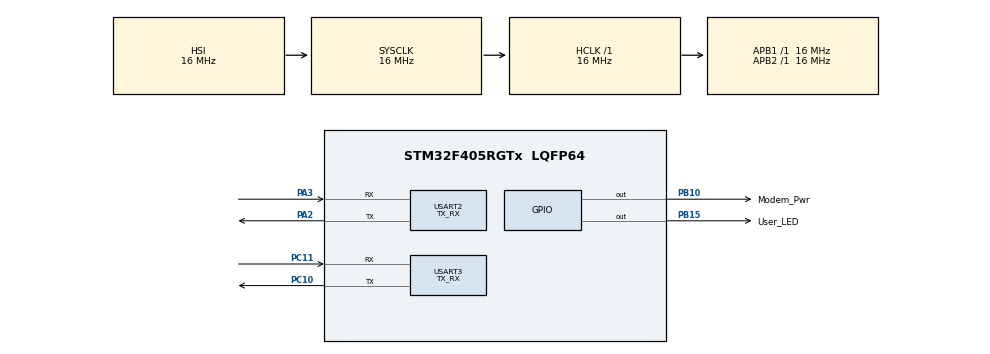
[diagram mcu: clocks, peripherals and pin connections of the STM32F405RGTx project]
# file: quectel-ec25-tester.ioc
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Dma.Request0=USART3_RX
Dma.Request1=USART2_RX
Dma.USART2_RX.1.Direction=DMA_PERIPH_TO_MEMORY
Dma.USART2_RX.1.FIFOMode=DMA_FIFOMODE_DISABLE
Dma.USART2_RX.1.Instance=DMA1_Stream5
Dma.USART2_RX.1.MemDataAlignment=DMA_MDATAALIGN_BYTE
Dma.USART2_RX.1.MemInc=DMA_MINC_ENABLE
Dma.USART2_RX.1.Mode=DMA_CIRCULAR
Dma.USART2_RX.1.PeriphDataAlignment=DMA_PDATAALIGN_BYTE
Dma.USART2_RX.1.PeriphInc=DMA_PINC_DISABLE
Dma.USART2_RX.1.Priority=DMA_PRIORITY_LOW
Dma.USART3_RX.0.Direction=DMA_PERIPH_TO_MEMORY
Dma.USART3_RX.0.FIFOMode=DMA_FIFOMODE_DISABLE
Dma.USART3_RX.0.Instance=DMA1_Stream1
Dma.USART3_RX.0.MemDataAlignment=DMA_MDATAALIGN_BYTE
Dma.USART3_RX.0.MemInc=DMA_MINC_ENABLE
Dma.USART3_RX.0.Mode=DMA_CIRCULAR
Dma.USART3_RX.0.PeriphDataAlignment=DMA_PDATAALIGN_BYTE
Dma.USART3_RX.0.PeriphInc=DMA_PINC_DISABLE
Dma.USART3_RX.0.Priority=DMA_PRIORITY_LOW
FREERTOS.Events01=FreeRTOS_Event_MQTT,Static,FreeRTOS_Event_MQTTControlBlock
FREERTOS.Mutexes01=ModemMutex,Static,ModemMutexControlBlock;MqttMutex,Static,MqttMutexControlBlock
FREERTOS.Tasks01=OS_Thread,24,512,OS_Run,As weak,NULL,Static,OS_ThreadBuffer,OS_ThreadControlBlock;Modem_Thread,8,1024,MDM_Run,As external,NULL,Static,Modem_ThreadBuffer,Modem_ThreadControlBlock;MQTT_Thread,8,1024,MQTT_Run,As external,NULL,Static,MQTT_ThreadBuffer,MQTT_ThreadControlBlock
FREERTOS.configUSE_NEWLIB_REENTRANT=1
Mcu.Family=STM32F4
Mcu.Name=STM32F405RGTx
Mcu.Package=LQFP64
NVIC.DMA1_Stream1_IRQn=true\:5\:0\:false\:false\:true\:true\:false\:true\:true
NVIC.DMA1_Stream5_IRQn=true\:5\:0\:false\:false\:true\:true\:false\:true\:true
NVIC.HASH_RNG_IRQn=true\:5\:0\:false\:false\:true\:true\:true\:true\:true
NVIC.PriorityGroup=NVIC_PRIORITYGROUP_4
NVIC.TIM1_UP_TIM10_IRQn=true\:15\:0\:false\:false\:true\:false\:false\:true\:true
NVIC.TimeBase=TIM1_UP_TIM10_IRQn
NVIC.TimeBaseIP=TIM1
NVIC.USART2_IRQn=true\:5\:0\:false\:false\:true\:true\:true\:true\:true
NVIC.USART3_IRQn=true\:5\:0\:false\:false\:true\:true\:true\:true\:true
PA13.Mode=Serial_Wire
PA13.Signal=SYS_JTMS-SWDIO
PA14.Mode=Serial_Wire
PA14.Signal=SYS_JTCK-SWCLK
PA2.Mode=Asynchronous
PA2.Signal=USART2_TX
PA3.Mode=Asynchronous
PA3.Signal=USART2_RX
PB10.GPIO_Label=Modem_Pwr
PB10.Signal=GPIO_Output
PB15.GPIO_Label=User_LED
PB15.Signal=GPIO_Output
PC10.Mode=Asynchronous
PC10.Signal=USART3_TX
PC11.Mode=Asynchronous
PC11.Signal=USART3_RX
ProjectManager.HeapSize=0x200
ProjectManager.StackSize=0x400
ProjectManager.TargetToolchain=STM32CubeIDE
RCC.AHBFreq_Value=16000000
RCC.APB1Freq_Value=16000000
RCC.APB2Freq_Value=16000000
RCC.CortexFreq_Value=16000000
RCC.HSE_VALUE=25000000
RCC.HSI_VALUE=16000000
RCC.LSE_VALUE=32768
RCC.SYSCLKFreq_VALUE=16000000
RCC.VCOOutputFreq_Value=192000000
USART2.Mode=MODE_TX_RX
USART2.VirtualMode=VM_ASYNC
USART3.Mode=MODE_TX_RX
USART3.VirtualMode=VM_ASYNC
VP_FREERTOS_VS_CMSIS_V2.Mode=CMSIS_V2
VP_RNG_VS_RNG.Mode=RNG_Activate
VP_SYS_VS_tim1.Mode=TIM1
board=custom

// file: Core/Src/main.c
/* USER CODE BEGIN Header */
/**
  ******************************************************************************
  * @file           : main.c
  * @brief          : Main program body
  ******************************************************************************
  * @attention
  *
  * Copyright (c) 2022 STMicroelectronics.
  * All rights reserved.
  *
  * This software is licensed under terms that can be found in the LICENSE file
  * in the root directory of this software component.
  * If no LICENSE file comes with this software, it is provided AS-IS.
  *
  ******************************************************************************
  */
/* USER CODE END Header */
#include "main.h"
#include "cmsis_os.h"
#include "dma.h"
#include "rng.h"
#include "usart.h"
#include "gpio.h"

void SystemClock_Config(void);
void MX_FREERTOS_Init(void);

int main(void)
{

  /* MCU Configuration--------------------------------------------------------*/

  /* Reset of all peripherals, Initializes the Flash interface and the Systick. */
  HAL_Init();

  /* Configure the system clock */
  SystemClock_Config();

  /* Initialize all configured peripherals */
  MX_GPIO_Init();
  MX_DMA_Init();
  MX_USART3_UART_Init();
  MX_USART2_UART_Init();
  MX_RNG_Init();

  /* Init scheduler */
  osKernelInitialize();  /* Call init function for freertos objects (in freertos.c) */
  MX_FREERTOS_Init();

  /* Start scheduler */
  osKernelStart();

  /* We should never get here as control is now taken by the scheduler */
  /* Infinite loop */
  while (1)
  {

  }
}

void SystemClock_Config(void)
{
  RCC_OscInitTypeDef RCC_OscInitStruct = {0};
  RCC_ClkInitTypeDef RCC_ClkInitStruct = {0};

  /** Configure the main internal regulator output voltage
  */
  __HAL_RCC_PWR_CLK_ENABLE();
  __HAL_PWR_VOLTAGESCALING_CONFIG(PWR_REGULATOR_VOLTAGE_SCALE1);

  /** Initializes the RCC Oscillators according to the specified parameters
  * in the RCC_OscInitTypeDef structure.
  */
  RCC_OscInitStruct.OscillatorType = RCC_OSCILLATORTYPE_HSI;
  RCC_OscInitStruct.HSIState = RCC_HSI_ON;
  RCC_OscInitStruct.HSICalibrationValue = RCC_HSICALIBRATION_DEFAULT;
  RCC_OscInitStruct.PLL.PLLState = RCC_PLL_ON;
  RCC_OscInitStruct.PLL.PLLSource = RCC_PLLSOURCE_HSI;
  RCC_OscInitStruct.PLL.PLLM = 16;
  RCC_OscInitStruct.PLL.PLLN = 192;
  RCC_OscInitStruct.PLL.PLLP = RCC_PLLP_DIV2;
  RCC_OscInitStruct.PLL.PLLQ = 4;
  if (HAL_RCC_OscConfig(&RCC_OscInitStruct) != HAL_OK)
  {
    Error_Handler();
  }

  /** Initializes the CPU, AHB and APB buses clocks
  */
  RCC_ClkInitStruct.ClockType = RCC_CLOCKTYPE_HCLK|RCC_CLOCKTYPE_SYSCLK
                              |RCC_CLOCKTYPE_PCLK1|RCC_CLOCKTYPE_PCLK2;
  RCC_ClkInitStruct.SYSCLKSource = RCC_SYSCLKSOURCE_HSI;
  RCC_ClkInitStruct.AHBCLKDivider = RCC_SYSCLK_DIV1;
  RCC_ClkInitStruct.APB1CLKDivider = RCC_HCLK_DIV1;
  RCC_ClkInitStruct.APB2CLKDivider = RCC_HCLK_DIV1;

  if (HAL_RCC_ClockConfig(&RCC_ClkInitStruct, FLASH_LATENCY_0) != HAL_OK)
  {
    Error_Handler();
  }
}

void HAL_TIM_PeriodElapsedCallback(TIM_HandleTypeDef *htim)
{
  if (htim->Instance == TIM1) {
    HAL_IncTick();
  }
}

void Error_Handler(void)
{
  __disable_irq();
  while (1)
  {
  }
}

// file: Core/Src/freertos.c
/* USER CODE BEGIN Header */
/**
  ******************************************************************************
  * File Name          : freertos.c
  * Description        : Code for freertos applications
  ******************************************************************************
  * @attention
  *
  * Copyright (c) 2022 STMicroelectronics.
  * All rights reserved.
  *
  * This software is licensed under terms that can be found in the LICENSE file
  * in the root directory of this software component.
  * If no LICENSE file comes with this software, it is provided AS-IS.
  *
  ******************************************************************************
  */
/* USER CODE END Header */

#include "FreeRTOS.h"
#include "task.h"
#include "main.h"
#include "cmsis_os.h"

/* USER CODE BEGIN Includes */
#include <os.h>
/* USER CODE END Includes */

typedef StaticTask_t osStaticThreadDef_t;
typedef StaticSemaphore_t osStaticMutexDef_t;
typedef StaticEventGroup_t osStaticEventGroupDef_t;

/* Definitions for OS_Thread */
osThreadId_t OS_ThreadHandle;
uint32_t OS_ThreadBuffer[ 512 ];
osStaticThreadDef_t OS_ThreadControlBlock;
const osThreadAttr_t OS_Thread_attributes = {
  .name = "OS_Thread",
  .cb_mem = &OS_ThreadControlBlock,
  .cb_size = sizeof(OS_ThreadControlBlock),
  .stack_mem = &OS_ThreadBuffer[0],
  .stack_size = sizeof(OS_ThreadBuffer),
  .priority = (osPriority_t) osPriorityNormal,
};
/* Definitions for Modem_Thread */
osThreadId_t Modem_ThreadHandle;
uint32_t Modem_ThreadBuffer[ 1024 ];
osStaticThreadDef_t Modem_ThreadControlBlock;
const osThreadAttr_t Modem_Thread_attributes = {
  .name = "Modem_Thread",
  .cb_mem = &Modem_ThreadControlBlock,
  .cb_size = sizeof(Modem_ThreadControlBlock),
  .stack_mem = &Modem_ThreadBuffer[0],
  .stack_size = sizeof(Modem_ThreadBuffer),
  .priority = (osPriority_t) osPriorityLow,
};
/* Definitions for MQTT_Thread */
osThreadId_t MQTT_ThreadHandle;
uint32_t MQTT_ThreadBuffer[ 1024 ];
osStaticThreadDef_t MQTT_ThreadControlBlock;
const osThreadAttr_t MQTT_Thread_attributes = {
  .name = "MQTT_Thread",
  .cb_mem = &MQTT_ThreadControlBlock,
  .cb_size = sizeof(MQTT_ThreadControlBlock),
  .stack_mem = &MQTT_ThreadBuffer[0],
  .stack_size = sizeof(MQTT_ThreadBuffer),
  .priority = (osPriority_t) osPriorityLow,
};
/* Definitions for ModemMutex */
osMutexId_t ModemMutexHandle;
osStaticMutexDef_t ModemMutexControlBlock;
const osMutexAttr_t ModemMutex_attributes = {
  .name = "ModemMutex",
  .cb_mem = &ModemMutexControlBlock,
  .cb_size = sizeof(ModemMutexControlBlock),
};
/* Definitions for MqttMutex */
osMutexId_t MqttMutexHandle;
osStaticMutexDef_t MqttMutexControlBlock;
const osMutexAttr_t MqttMutex_attributes = {
  .name = "MqttMutex",
  .cb_mem = &MqttMutexControlBlock,
  .cb_size = sizeof(MqttMutexControlBlock),
};
/* Definitions for FreeRTOS_Event_MQTT */
osEventFlagsId_t FreeRTOS_Event_MQTTHandle;
osStaticEventGroupDef_t FreeRTOS_Event_MQTTControlBlock;
const osEventFlagsAttr_t FreeRTOS_Event_MQTT_attributes = {
  .name = "FreeRTOS_Event_MQTT",
  .cb_mem = &FreeRTOS_Event_MQTTControlBlock,
  .cb_size = sizeof(FreeRTOS_Event_MQTTControlBlock),
};

void OS_Run(void *argument);
extern void MDM_Run(void *argument);
extern void MQTT_Run(void *argument);

void MX_FREERTOS_Init(void); /* (MISRA C 2004 rule 8.1) */

void MX_FREERTOS_Init(void) {
  /* Create the mutex(es) */
  /* creation of ModemMutex */
  ModemMutexHandle = osMutexNew(&ModemMutex_attributes);

  /* creation of MqttMutex */
  MqttMutexHandle = osMutexNew(&MqttMutex_attributes);

  /* Create the thread(s) */
  /* creation of OS_Thread */
  OS_ThreadHandle = osThreadNew(OS_Run, NULL, &OS_Thread_attributes);

  /* creation of Modem_Thread */
  Modem_ThreadHandle = osThreadNew(MDM_Run, NULL, &Modem_Thread_attributes);

  /* creation of MQTT_Thread */
  MQTT_ThreadHandle = osThreadNew(MQTT_Run, NULL, &MQTT_Thread_attributes);

  /* creation of FreeRTOS_Event_MQTT */
  FreeRTOS_Event_MQTTHandle = osEventFlagsNew(&FreeRTOS_Event_MQTT_attributes);

  /* USER CODE BEGIN RTOS_EVENTS */
  /* add events, ... */
  OS_Services_Init();
  /* USER CODE END RTOS_EVENTS */

}

__weak void OS_Run(void *argument)
{
  for(;;)
  {
    osDelay(1);
  }
}
